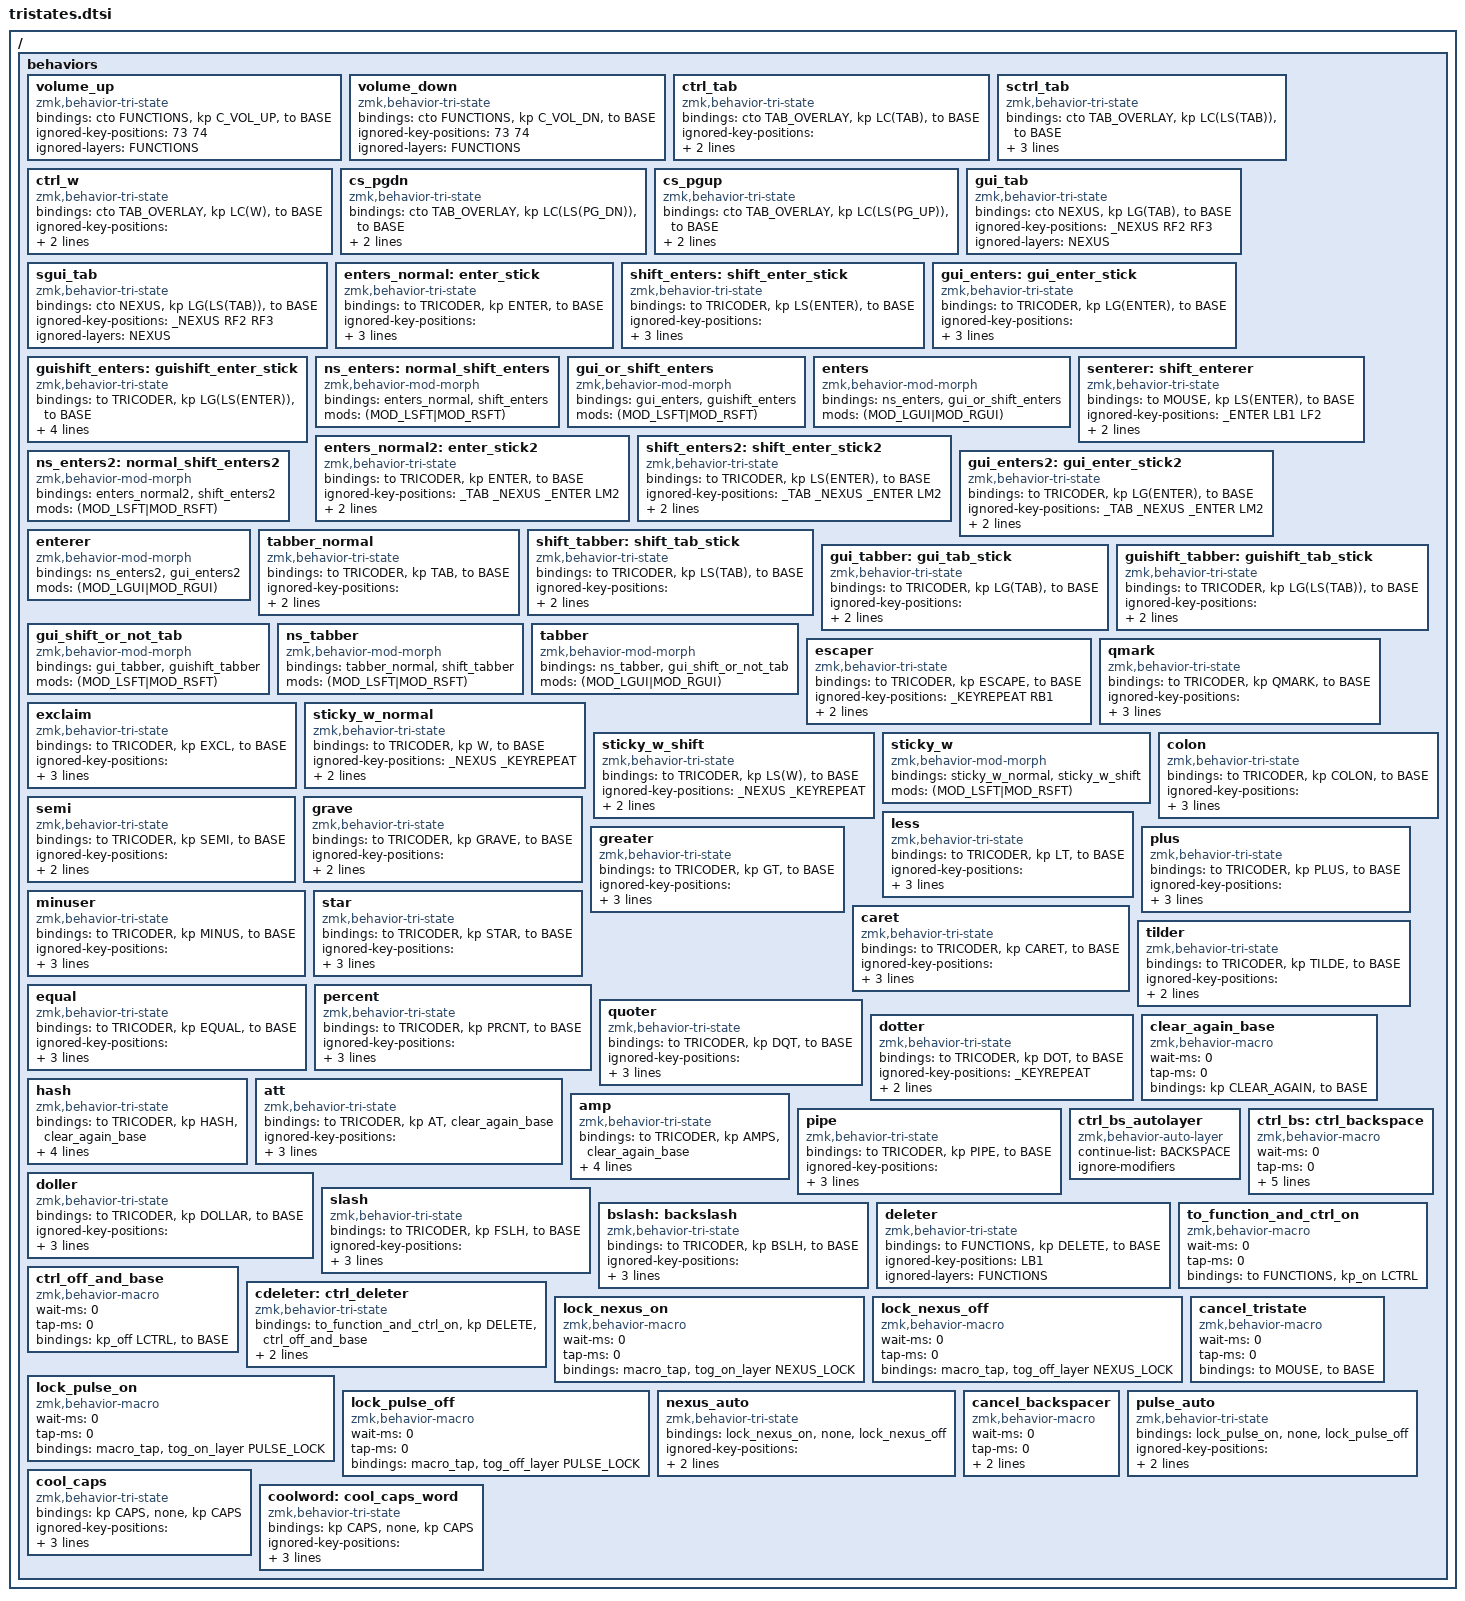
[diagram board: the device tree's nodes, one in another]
/ {
	behaviors {

    #define _RSHIFT RT1
    #define _PULSE LM1
    #define _NEXUS LB3
    #define _ENTER LB2
    #define _TAB LB4
    #define _KEYREPEAT RM1
    #define _NUMLEFT LH6
    #define _NUMRIGHT RH6

		volume_up: volume_up {
				compatible = "zmk,behavior-tri-state";
				#binding-cells = <0>;
				bindings = <&cto FUNCTIONS>, <&kp C_VOL_UP>, <&to BASE>;
				ignored-key-positions = <73 74>;
				ignored-layers = <FUNCTIONS>;
		};

		volume_down: volume_down {
				compatible = "zmk,behavior-tri-state";
				#binding-cells = <0>;
				bindings = <&cto FUNCTIONS>, <&kp C_VOL_DN>, <&to BASE>;
				ignored-key-positions = <73 74>;
				ignored-layers = <FUNCTIONS>;
		};

		ctrl_tab: ctrl_tab {
				compatible = "zmk,behavior-tri-state";
				#binding-cells = <0>;
				bindings = <&cto TAB_OVERLAY>, <&kp LC(TAB)>, <&to BASE>;
				ignored-key-positions = <_PULSE LF2 LF3 RF2 RF3 LM5 LB1>;
				ignored-layers = <TAB_OVERLAY>;
		};

		sctrl_tab: sctrl_tab {
				compatible = "zmk,behavior-tri-state";
				#binding-cells = <0>;
				bindings = <&cto TAB_OVERLAY>, <&kp LC(LS(TAB))>, <&to BASE>;
				ignored-key-positions = <_PULSE LF2 LF3 RF2 RF3 LM5 LB1>;
				ignored-layers = <TAB_OVERLAY>;
		};

		ctrl_w: ctrl_w {
				compatible = "zmk,behavior-tri-state";
				#binding-cells = <0>;
				bindings = <&cto TAB_OVERLAY>, <&kp LC(W)>, <&to BASE>;
				ignored-key-positions = <_NEXUS LF2 LF3 RF2 RF3 LM5 LB1>;
				ignored-layers = <NEXUS TAB_OVERLAY>;
		};

		cs_pgdn: cs_pgdn {
				compatible = "zmk,behavior-tri-state";
				#binding-cells = <0>;
				bindings = <&cto TAB_OVERLAY>, <&kp LC(LS(PG_DN))>, <&to BASE>;
				ignored-key-positions = <LF2 LF3 RF2 RF3 LM5 LB1>;
				ignored-layers = <TAB_OVERLAY>;
		};

		cs_pgup: cs_pgup {
				compatible = "zmk,behavior-tri-state";
				#binding-cells = <0>;
				bindings = <&cto TAB_OVERLAY>, <&kp LC(LS(PG_UP))>, <&to BASE>;
				ignored-key-positions = <LF2 LF3 RF2 RF3 LM5 LB1>;
				ignored-layers = <TAB_OVERLAY>;
		};

		gui_tab: gui_tab {
				compatible = "zmk,behavior-tri-state";
				#binding-cells = <0>;
				bindings = <&cto NEXUS>, <&kp LG(TAB)>, <&to BASE>;
				ignored-key-positions = <_NEXUS RF2 RF3>;
				ignored-layers = <NEXUS>;
		};

		sgui_tab: sgui_tab {
				compatible = "zmk,behavior-tri-state";
				#binding-cells = <0>;
				bindings = <&cto NEXUS>, <&kp LG(LS(TAB))>, <&to BASE>;
				ignored-key-positions = <_NEXUS RF2 RF3>;
				ignored-layers = <NEXUS>;
		};

		enters_normal: enter_stick {
				compatible = "zmk,behavior-tri-state";
				#binding-cells = <0>;
				bindings = <&to TRICODER>, <&kp ENTER>, <&to BASE>;
				ignored-key-positions = <_TAB _NEXUS _ENTER _RSHIFT>;
				ignored-layers = <TRICODER>;
        timeout-ms = <2000>;
		};
    /* Ath, þetta er frekar bjánaleg lausn til að láta sticky shift virka með enter (handa inni mods virka augljóslega enn) */
		shift_enters: shift_enter_stick {
				compatible = "zmk,behavior-tri-state";
				#binding-cells = <0>;
				bindings = <&to TRICODER>, <&kp LS(ENTER)>, <&to BASE>;
				ignored-key-positions = <_TAB _NEXUS _ENTER _RSHIFT>;
				ignored-layers = <TRICODER>;
        timeout-ms = <2000>;
		};
		gui_enters: gui_enter_stick {
				compatible = "zmk,behavior-tri-state";
				#binding-cells = <0>;
				bindings = <&to TRICODER>, <&kp LG(ENTER)>, <&to BASE>;
				ignored-key-positions = <_TAB _NEXUS _ENTER _RSHIFT>;
				ignored-layers = <TRICODER>;
        timeout-ms = <2000>;
		};
		guishift_enters: guishift_enter_stick {
				compatible = "zmk,behavior-tri-state";
				#binding-cells = <0>;
				bindings = <&to TRICODER>, <&kp LG(LS(ENTER))>, <&to BASE>;
				ignored-key-positions = <_TAB _NEXUS _ENTER _RSHIFT>;
				ignored-layers = <TRICODER>;
        timeout-ms = <2000>;
		};
		ns_enters: normal_shift_enters {
			compatible = "zmk,behavior-mod-morph";
			#binding-cells = <0>;
			bindings = <&enters_normal>, <&shift_enters>;
			mods = <(MOD_LSFT|MOD_RSFT)>;
		};
		gui_or_shift_enters: gui_or_shift_enters {
			compatible = "zmk,behavior-mod-morph";
			#binding-cells = <0>;
			bindings = <&gui_enters>, <&guishift_enters>;
			mods = <(MOD_LSFT|MOD_RSFT)>;
		};
		enters: enters {
			compatible = "zmk,behavior-mod-morph";
			#binding-cells = <0>;
			bindings = <&ns_enters>, <&gui_or_shift_enters>;
			mods = <(MOD_LGUI|MOD_RGUI)>;
		};
		senterer: shift_enterer {
				compatible = "zmk,behavior-tri-state";
				#binding-cells = <0>;
				bindings = <&to MOUSE>, <&kp LS(ENTER)>, <&to BASE>;
				ignored-key-positions = <_ENTER LB1 LF2>;
				ignored-layers = <MOUSE>;
        timeout-ms = <2000>;
		};
		enters_normal2: enter_stick2 {
				compatible = "zmk,behavior-tri-state";
				#binding-cells = <0>;
				bindings = <&to TRICODER>, <&kp ENTER>, <&to BASE>;
				ignored-key-positions = <_TAB _NEXUS _ENTER LM2>;
				ignored-layers = <TRICODER>;
        timeout-ms = <2000>;
		};
    /* Ath, þetta er frekar bjánaleg lausn til að láta sticky shift virka með enter (handa inni mods virka augljóslega enn) */
		shift_enters2: shift_enter_stick2 {
				compatible = "zmk,behavior-tri-state";
				#binding-cells = <0>;
				bindings = <&to TRICODER>, <&kp LS(ENTER)>, <&to BASE>;
				ignored-key-positions = <_TAB _NEXUS _ENTER LM2>;
				ignored-layers = <TRICODER>;
        timeout-ms = <2000>;
		};
		gui_enters2: gui_enter_stick2 {
				compatible = "zmk,behavior-tri-state";
				#binding-cells = <0>;
				bindings = <&to TRICODER>, <&kp LG(ENTER)>, <&to BASE>;
				ignored-key-positions = <_TAB _NEXUS _ENTER LM2>;
				ignored-layers = <TRICODER>;
        timeout-ms = <2000>;
		};
		ns_enters2: normal_shift_enters2 {
			compatible = "zmk,behavior-mod-morph";
			#binding-cells = <0>;
			bindings = <&enters_normal2>, <&shift_enters2>;
			mods = <(MOD_LSFT|MOD_RSFT)>;
		};
		enterer: enterer {
			compatible = "zmk,behavior-mod-morph";
			#binding-cells = <0>;
			bindings = <&ns_enters2>, <&gui_enters2>;
			mods = <(MOD_LGUI|MOD_RGUI)>;
		};
    

		tabber_normal: tabber_normal {
				compatible = "zmk,behavior-tri-state";
				#binding-cells = <0>;
				bindings = <&to TRICODER>, <&kp TAB>, <&to BASE>;
				/* ignored-key-positions = <_KEYREPEAT LM1 LB1 _TAB _RSHIFT>; */
				ignored-key-positions = <_KEYREPEAT LM1 LB1 _RSHIFT>;
				ignored-layers = <TRICODER>;
		};
		shift_tabber: shift_tab_stick {
				compatible = "zmk,behavior-tri-state";
				#binding-cells = <0>;
				/* bindings = <&to TRICODER>, <&kpsk LS(TAB) LSHIFT>, <&to BASE>; */
				bindings = <&to TRICODER>, <&kp LS(TAB)>, <&to BASE>;
				/* ignored-key-positions = <_KEYREPEAT LM1 LB1 _TAB _RSHIFT>; */
				ignored-key-positions = <_KEYREPEAT LM1 LB1 _RSHIFT>;
				ignored-layers = <TRICODER>;
		};
		gui_tabber: gui_tab_stick {
				compatible = "zmk,behavior-tri-state";
				#binding-cells = <0>;
				/* bindings = <&to TRICODER>, <&kpsk LG(TAB) LGUI>, <&cto BASE>; */
				bindings = <&to TRICODER>, <&kp LG(TAB)>, <&to BASE>;
				/* ignored-key-positions = <_KEYREPEAT LM1 LB1 _TAB _RSHIFT>; */
				ignored-key-positions = <_KEYREPEAT LM1 LB1 _RSHIFT>;
				ignored-layers = <TRICODER>;
		};
		guishift_tabber: guishift_tab_stick {
				compatible = "zmk,behavior-tri-state";
				#binding-cells = <0>;
				/* bindings = <&to TRICODER>, <&kpsk LG(LS(TAB)) LS(LGUI)>, <&cto BASE>; */
				bindings = <&to TRICODER>, <&kp LG(LS(TAB))>, <&to BASE>;
				/* ignored-key-positions = <_KEYREPEAT LM1 LB1 _TAB _RSHIFT>; */
				ignored-key-positions = <_KEYREPEAT LM1 LB1 _RSHIFT>;
				ignored-layers = <TRICODER>;
		};
		gui_shift_or_not_tab: gui_shift_or_not_tab {
			compatible = "zmk,behavior-mod-morph";
			#binding-cells = <0>;
			bindings = <&gui_tabber>, <&guishift_tabber>;
			mods = <(MOD_LSFT|MOD_RSFT)>;
		};
		ns_tabber: ns_tabber {
			compatible = "zmk,behavior-mod-morph";
			#binding-cells = <0>;
			bindings = <&tabber_normal>, <&shift_tabber>;
			mods = <(MOD_LSFT|MOD_RSFT)>;
		};
		tabber: tabber {
			compatible = "zmk,behavior-mod-morph";
			#binding-cells = <0>;
			bindings = <&ns_tabber>, <&gui_shift_or_not_tab>;
			mods = <(MOD_LGUI|MOD_RGUI)>;
		};

		escaper: escaper {
				compatible = "zmk,behavior-tri-state";
				#binding-cells = <0>;
				bindings = <&to TRICODER>, <&kp ESCAPE>, <&to BASE>;
				ignored-key-positions = <_KEYREPEAT RB1>;
				ignored-layers = <TRICODER>;
        timeout-ms = <2000>;
		};

		qmark: qmark {
				compatible = "zmk,behavior-tri-state";
				#binding-cells = <0>;
				bindings = <&to TRICODER>, <&kp QMARK>, <&to BASE>;
				ignored-key-positions = <_NEXUS _ENTER _TAB _KEYREPEAT _NUMLEFT _NUMRIGHT RT1>;
				ignored-layers = <TRICODER>;
        timeout-ms = <2000>;
		};

		exclaim: exclaim {
				compatible = "zmk,behavior-tri-state";
				#binding-cells = <0>;
				bindings = <&to TRICODER>, <&kp EXCL>, <&to BASE>;
				ignored-key-positions = <_NEXUS _ENTER _TAB _KEYREPEAT _NUMLEFT _NUMRIGHT RT1>;
				ignored-layers = <TRICODER>;
        timeout-ms = <2000>;
		};

		/* sticky_w_normal: sticky_w_normal { */
		sticky_w_normal: sticky_w_normal {
				compatible = "zmk,behavior-tri-state";
				#binding-cells = <0>;
				bindings = <&to TRICODER>, <&kp W>, <&to BASE>;
				ignored-key-positions = <_NEXUS _KEYREPEAT>;
				ignored-layers = <TRICODER>;
        timeout-ms = <4000>;
		};
		sticky_w_shift: sticky_w_shift {
				compatible = "zmk,behavior-tri-state";
				#binding-cells = <0>;
				bindings = <&to TRICODER>, <&kp LS(W)>, <&to BASE>;
				ignored-key-positions = <_NEXUS _KEYREPEAT>;
				ignored-layers = <TRICODER>;
		      timeout-ms = <4000>;
		};
		/* sticky_w_ctrl: sticky_w_ctrl { */
		/* 		compatible = "zmk,behavior-tri-state"; */
		/* 		#binding-cells = <0>; */
		/* 		bindings = <&to NEXUS_LOCK>, <&kp LC(W)>, <&to BASE>; */
		/* 		ignored-key-positions = <_NEXUS LM2>; */
		/* 		ignored-layers = <BASE NEXUS NEXUS_LOCK>; */
		/*       timeout-ms = <2000>; */
		/* }; */
		sticky_w: sticky_w {
			compatible = "zmk,behavior-mod-morph";
			#binding-cells = <0>;
			bindings = <&sticky_w_normal>, <&sticky_w_shift>;
			mods = <(MOD_LSFT|MOD_RSFT)>;
		};

		colon: colon {
				compatible = "zmk,behavior-tri-state";
				#binding-cells = <0>;
				bindings = <&to TRICODER>, <&kp COLON>, <&to BASE>;
				ignored-key-positions = <_ENTER _TAB _KEYREPEAT _NUMLEFT _NUMRIGHT>;
				/* ignored-key-positions = <_KEYREPEAT _NUMLEFT _NUMRIGHT>; */
				ignored-layers = <TRICODER>;
        timeout-ms = <2000>;
		};

		semi: semi {
				compatible = "zmk,behavior-tri-state";
				#binding-cells = <0>;
				bindings = <&to TRICODER>, <&kp SEMI>, <&to BASE>;
				ignored-key-positions = <_ENTER _TAB _KEYREPEAT _NUMLEFT _NUMRIGHT>;
				/* ignored-key-positions = <_KEYREPEAT _NUMLEFT _NUMRIGHT>; */
				ignored-layers = <TRICODER>;
		};

		grave: grave {
				compatible = "zmk,behavior-tri-state";
				#binding-cells = <0>;
				bindings = <&to TRICODER>, <&kp GRAVE>, <&to BASE>;
				/* ignored-key-positions = <_ENTER _KEYREPEAT _NUMLEFT _NUMRIGHT>; */
				ignored-key-positions = <_KEYREPEAT _NUMLEFT _NUMRIGHT>;
				ignored-layers = <TRICODER>;
		};

		less: less {
				compatible = "zmk,behavior-tri-state";
				#binding-cells = <0>;
				bindings = <&to TRICODER>, <&kp LT>, <&to BASE>;
				ignored-key-positions = <_KEYREPEAT _NUMLEFT _NUMRIGHT>;
				ignored-layers = <TRICODER>;
        timeout-ms = <2000>;
		};

		greater: greater {
				compatible = "zmk,behavior-tri-state";
				#binding-cells = <0>;
				bindings = <&to TRICODER>, <&kp GT>, <&to BASE>;
				ignored-key-positions = <_KEYREPEAT _NUMLEFT _NUMRIGHT>;
				ignored-layers = <TRICODER>;
        timeout-ms = <2000>;
		};

		plus: plus {
				compatible = "zmk,behavior-tri-state";
				#binding-cells = <0>;
				bindings = <&to TRICODER>, <&kp PLUS>, <&to BASE>;
				ignored-key-positions = <_KEYREPEAT _NUMLEFT _NUMRIGHT>;
				ignored-layers = <TRICODER>;
        timeout-ms = <2000>;
		};

		minuser: minuser {
				compatible = "zmk,behavior-tri-state";
				#binding-cells = <0>;
				bindings = <&to TRICODER>, <&kp MINUS>, <&to BASE>;
				ignored-key-positions = <_KEYREPEAT _NUMLEFT _NUMRIGHT>;
				ignored-layers = <TRICODER>;
        timeout-ms = <2000>;
		};

		star: star {
				compatible = "zmk,behavior-tri-state";
				#binding-cells = <0>;
				bindings = <&to TRICODER>, <&kp STAR>, <&to BASE>;
				ignored-key-positions = <_KEYREPEAT RN2 _NUMLEFT _NUMRIGHT>;
				ignored-layers = <TRICODER>;
        timeout-ms = <2000>;
		};

		caret: caret {
				compatible = "zmk,behavior-tri-state";
				#binding-cells = <0>;
				bindings = <&to TRICODER>, <&kp CARET>, <&to BASE>;
				ignored-key-positions = <_KEYREPEAT _NUMLEFT _NUMRIGHT>;
				ignored-layers = <TRICODER>;
        timeout-ms = <2000>;
		};

		tilder: tilder {
				compatible = "zmk,behavior-tri-state";
				#binding-cells = <0>;
				bindings = <&to TRICODER>, <&kp TILDE>, <&to BASE>;
				ignored-key-positions = <_KEYREPEAT _NUMLEFT _NUMRIGHT>;
				ignored-layers = <TRICODER>;
		};


		equal: equal {
				compatible = "zmk,behavior-tri-state";
				#binding-cells = <0>;
				bindings = <&to TRICODER>, <&kp EQUAL>, <&to BASE>;
				ignored-key-positions = <_KEYREPEAT _NUMLEFT _NUMRIGHT>;
				ignored-layers = <TRICODER>;
        timeout-ms = <2000>;
		};

		percent: percent {
				compatible = "zmk,behavior-tri-state";
				#binding-cells = <0>;
				bindings = <&to TRICODER>, <&kp PRCNT>, <&to BASE>;
				ignored-key-positions = <_KEYREPEAT _NUMLEFT _NUMRIGHT>;
				ignored-layers = <TRICODER>;
        timeout-ms = <2000>;
		};

		quoter: quoter {
				compatible = "zmk,behavior-tri-state";
				#binding-cells = <0>;
				bindings = <&to TRICODER>, <&kp DQT>, <&to BASE>;
				ignored-key-positions = <_KEYREPEAT _NUMLEFT _NUMRIGHT>;
				ignored-layers = <TRICODER>;
        timeout-ms = <2000>;
		};

		dotter: dotter {
				compatible = "zmk,behavior-tri-state";
				#binding-cells = <0>;
				bindings = <&to TRICODER>, <&kp DOT>, <&to BASE>;
				ignored-key-positions = <_KEYREPEAT>;
				ignored-layers = <TRICODER>;
        timeout-ms = <2000>;
		};

		clear_again_base: clear_again_base {
			compatible = "zmk,behavior-macro";
			#binding-cells = <0>;
			wait-ms = <0>;
			tap-ms = <0>;
			bindings = <&kp CLEAR_AGAIN>, <&to BASE>;
		};

		hash: hash {
				compatible = "zmk,behavior-tri-state";
				#binding-cells = <0>;
				bindings = <&to TRICODER>, <&kp HASH>, <&clear_again_base>;
				ignored-key-positions = <_KEYREPEAT _NUMLEFT _NUMRIGHT>;
				ignored-layers = <TRICODER>;
        timeout-ms = <2000>;
		};

		att: att {
				compatible = "zmk,behavior-tri-state";
				#binding-cells = <0>;
				bindings = <&to TRICODER>, <&kp AT>, <&clear_again_base>;
				ignored-key-positions = <_KEYREPEAT _NUMLEFT _NUMRIGHT>;
				ignored-layers = <TRICODER>;
        timeout-ms = <2000>;
		};

		amp: amp {
				compatible = "zmk,behavior-tri-state";
				#binding-cells = <0>;
				bindings = <&to TRICODER>, <&kp AMPS>, <&clear_again_base>;
				ignored-key-positions = <_KEYREPEAT _NUMLEFT _NUMRIGHT>;
				ignored-layers = <TRICODER>;
        timeout-ms = <2000>;
		};

		pipe: pipe {
				compatible = "zmk,behavior-tri-state";
				#binding-cells = <0>;
				bindings = <&to TRICODER>, <&kp PIPE>, <&to BASE>;
				ignored-key-positions = <_KEYREPEAT _NUMLEFT _NUMRIGHT>;
				ignored-layers = <TRICODER>;
        timeout-ms = <2000>;
		};

		/* ctrl_bs: ctrl_backspace { */
		/* 		compatible = "zmk,behavior-tri-state"; */
		/* 		#binding-cells = <0>; */
		/* 		bindings = <&kp_on LCTRL>, <&kp LC(BACKSPACE)>, <&kp_off LCTRL>; */
		/* 		ignored-key-positions = <RT1 LB1>; */
		/*       timeout-ms = <6000>; */
		/* }; */
    /* Auto-layer variant is more reliable than tri-state here. */
    ctrl_bs_autolayer: ctrl_bs_autolayer {
			compatible = "zmk,behavior-auto-layer";
			#binding-cells = <1>;
      continue-list = <BACKSPACE>;
      ignore-modifiers;
    };

		ctrl_bs: ctrl_backspace {
			compatible = "zmk,behavior-macro";
			#binding-cells = <0>;
      wait-ms = <0>;
      tap-ms = <0>;
      bindings
        = <&ctrl_bs_autolayer BACKSPACER>
        , <&macro_press &kp LCTRL>
        , <&macro_press &kp BACKSPACE>
        , <&macro_pause_for_release>
        , <&macro_release &kp BACKSPACE>
        , <&macro_release &kp LCTRL>
        ;
		};

		doller: doller {
				compatible = "zmk,behavior-tri-state";
				#binding-cells = <0>;
				bindings = <&to TRICODER>, <&kp DOLLAR>, <&to BASE>;
				ignored-key-positions = <_KEYREPEAT _NUMLEFT _NUMRIGHT>;
				ignored-layers = <TRICODER>;
        timeout-ms = <2000>;
		};
    
		slash: slash {
				compatible = "zmk,behavior-tri-state";
				#binding-cells = <0>;
				bindings = <&to TRICODER>, <&kp FSLH>, <&to BASE>;
				ignored-key-positions = <_KEYREPEAT _NUMLEFT _NUMRIGHT>;
				ignored-layers = <TRICODER>;
        timeout-ms = <2000>;
		};
    
	  bslash: backslash {
				compatible = "zmk,behavior-tri-state";
				#binding-cells = <0>;
				bindings = <&to TRICODER>, <&kp BSLH>, <&to BASE>;
				ignored-key-positions = <_KEYREPEAT _NUMLEFT _NUMRIGHT>;
				ignored-layers = <TRICODER>;
        timeout-ms = <2000>;
		};

		deleter: deleter {
				compatible = "zmk,behavior-tri-state";
				#binding-cells = <0>;
				bindings = <&to FUNCTIONS>, <&kp DELETE>, <&to BASE>;
				ignored-key-positions = <LB1>;
				ignored-layers = <FUNCTIONS>;
		};


		to_function_and_ctrl_on: to_function_and_ctrl_on {
			compatible = "zmk,behavior-macro";
			#binding-cells = <0>;
			wait-ms = <0>;
			tap-ms = <0>;
			bindings = <&to FUNCTIONS>, <&kp_on LCTRL>;
		};

		ctrl_off_and_base: ctrl_off_and_base {
			compatible = "zmk,behavior-macro";
			#binding-cells = <0>;
			wait-ms = <0>;
			tap-ms = <0>;
			bindings = <&kp_off LCTRL>, <&to BASE>;
		};

		cdeleter: ctrl_deleter {
				compatible = "zmk,behavior-tri-state";
				#binding-cells = <0>;
				bindings = <&to_function_and_ctrl_on>, <&kp DELETE>, <&ctrl_off_and_base>;
				ignored-key-positions = <LB1>;
				ignored-layers = <FUNCTIONS>;
		};

    lock_nexus_on: lock_nexus_on {
        compatible = "zmk,behavior-macro";
        #binding-cells = <0>;
        wait-ms = <0>;
        tap-ms = <0>;
        bindings = <&macro_tap &tog_on_layer NEXUS_LOCK>; // Uses Toggle, which survives the roll
    };
    lock_nexus_off: lock_nexus_off {
        compatible = "zmk,behavior-macro";
        #binding-cells = <0>;
        wait-ms = <0>;
        tap-ms = <0>;
        bindings = <&macro_tap &tog_off_layer NEXUS_LOCK>;
    };
    lock_pulse_on: lock_pulse_on {
        compatible = "zmk,behavior-macro";
        #binding-cells = <0>;
        wait-ms = <0>;
        tap-ms = <0>;
        bindings = <&macro_tap &tog_on_layer PULSE_LOCK>; // Uses Toggle, which survives the roll
    };
    lock_pulse_off: lock_pulse_off {
        compatible = "zmk,behavior-macro";
        #binding-cells = <0>;
        wait-ms = <0>;
        tap-ms = <0>;
        bindings = <&macro_tap &tog_off_layer PULSE_LOCK>;
    };
		nexus_auto: nexus_auto {
			compatible = "zmk,behavior-tri-state";
			#binding-cells = <0>;
			bindings = <&lock_nexus_on>, <&none>, <&lock_nexus_off>;
			ignored-key-positions = <
			
		  /* left */
          2  3  4        \
		            14       \
		      24 25 26 27    \
		         37 38       \
		      48 49 50 51    \
		         67 68
		  /* right */
		16    18 19       \
		28 29 30 31 32    \
		40 41 42 43 44 45 \
		58 59 60 61 62    \
		75 76         
		  /* thumbs, 69 er space og 74 er R */
		   52          74             \
		 70           73                 \
		  71         72

			>;
				ignored-layers = <NEXUS NEXUS_LOCK>;
		};
		cancel_tristate: cancel_tristate {
			compatible = "zmk,behavior-macro";
			#binding-cells = <0>;
			wait-ms = <0>;
			tap-ms = <0>;
			bindings = <&to MOUSE>, <&to BASE>;
		};

		cancel_backspacer: cancel_backspacer {
			compatible = "zmk,behavior-macro";
			#binding-cells = <0>;
			wait-ms = <0>;
			tap-ms = <0>;
      /* Exit Backspacer, clear auto-layer state, and preserve one-shot shift behavior. */
			bindings = <&to MOUSE>, <&to BASE>, <&ctrl_bs_autolayer BACKSPACER>, <&sk LSHIFT>;
		};
		


		/*   left */
		/* 0  1  2  3  4       \ */
		/* 10 11 12 13 14 15    \ */
		/* 22 23 24 25 26 27    \ */
		/* 34 35 36 37 38 39    \ */
		/* 46 47 48 49 50 51    \ */
		/* 64 65 66 67 68 */
		/*   right */
		/* 5  6  7  8  9 \ */
		/* 16 17 18 19 20 21 \ */
		/* 28 29 30 31 32 33 \ */
		/* 40 41 42 43 44 45 \ */
		/* 58 59 60 61 62 63 \ */
		/* 75 76 77 78 79 */
		/*   thumbs, 69 er space og 74 er R */
		/* 69 52       57 74                \ */
		/*  70 53     56 73                 \ */
		/*   71 54   55 72 */

		pulse_auto: pulse_auto {
			compatible = "zmk,behavior-tri-state";
			#binding-cells = <0>;
			bindings = <&lock_pulse_on>, <&none>, <&lock_pulse_off>;
			ignored-key-positions = <
			
		/*   left */
          2  3  4        \
		         13 14       \
		22    24 25 26 27    \
		      36 37 38 39    \
		   47 48 49 50 51    \
		         67 68       \
		/*   right */
		   17 18 19    21 \
		28 29 30 31       \
		40 41 42 43 44 45 \
		58 59 60 61 62    \
		75 76         
		/*   thumbs, 69 er space og 74 er R */
		               74                \
		 70                              \
		  71         72

			>;
				ignored-layers = <PULSE PULSE_LOCK>;
		};


		/* caps_and_test: caps_and_test { */
		/* 	compatible = "zmk,behavior-macro"; */
		/* 	#binding-cells = <0>; */
		/* 	wait-ms = <0>; */
		/* 	tap-ms = <0>; */
		/* 	bindings = <&kp CAPS>, <&kp T>; */
		/* }; */


		cool_caps: cool_caps {
			compatible = "zmk,behavior-tri-state";
			#binding-cells = <0>;
			bindings = <&kp CAPS>, <&none>, <&kp CAPS>;
			ignored-key-positions = <
			
		/*   left */
		0  1  2  3  4       \
		10 11 12 13 14 15    \
		22    24 25 26 27    \
		34 35 36 37 38 39    \
		46 47 48 49 50 51    \
		64 65 66 67 68
		/*   right */
		5  6  7  8  9 \
		16 17 18 19    21 \
		28 29 30 31 32 33 \
		40 41 42 43 44 45 \
		58 59 60 61 62 63 \
		75 76 77 78 79
		/*   thumbs, 69 er space og 74 er R */
		69 52       57 74                \
		 70           73                 \
		  71 54   55 72

				>;
					ignored-layers = <BASE NAV_WORD NUM_WORD NUM_WORD_PLUS ICE BACKSPACER PULSE PULSE_LOCK NEXUS NEXUS_LOCK TRICODER>;
			};

		coolword: cool_caps_word {
			compatible = "zmk,behavior-tri-state";
			#binding-cells = <0>;
			bindings = <&kp CAPS>, <&none>, <&kp CAPS>;
			ignored-key-positions = <
			
		/*   left */
		0  1  2  3  4       \
		10 11 12 13 14 15    \
		22    24 25 26 27    \
		34 35 36 37 38 39    \
		46 47 48 49 50 51    \
		64 65 66 67 68
		/*   right */
		5  6  7  8  9 \
		16 17 18 19    21 \
		28 29 30 31 32 33 \
		40 41 42 43 44 45 \
		58 59 60 61 62 63 \
		75 76 77 78 79
		/*   thumbs, 69 er space og 74 er R */
		   52       57 74                \
		 70           73                 \
		  71 54   55 72

			>;
				ignored-layers = <BASE NAV_WORD NUM_WORD NUM_WORD_PLUS PULSE PULSE_LOCK NEXUS NEXUS_LOCK TRICODER>;
		};

	};
};
